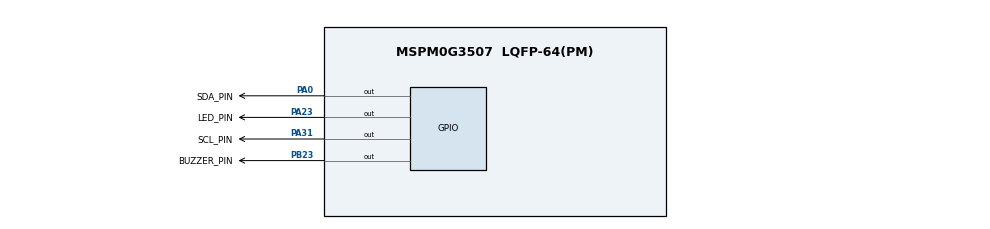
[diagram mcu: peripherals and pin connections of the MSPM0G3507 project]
/**
 * These arguments were used when this file was generated. They will be automatically applied on subsequent loads
 * via the GUI or CLI. Run CLI with '--help' for additional information on how to override these arguments.
 * @cliArgs --device "MSPM0G350X" --part "Default" --package "LQFP-64(PM)" --product "mspm0_sdk@2.11.00.07"
 * @v2CliArgs --device "MSPM0G3507" --package "LQFP-64(PM)" --product "mspm0_sdk@2.11.00.07"
 * @versions {"tool":"1.26.2+4477"}
 */

/**
 * Import the modules used in this configuration.
 */
const GPIO   = scripting.addModule("/ti/driverlib/GPIO", {}, false);
const GPIO1  = GPIO.addInstance();
const GPIO2  = GPIO.addInstance();
const GPIO3  = GPIO.addInstance();
const GPIO4  = GPIO.addInstance();
const SYSCTL = scripting.addModule("/ti/driverlib/SYSCTL");

/**
 * Write custom configuration values to the imported modules.
 */
GPIO1.$name                          = "LED";
GPIO1.associatedPins[0].$name        = "LED_PIN";
GPIO1.associatedPins[0].initialValue = "SET";
GPIO1.associatedPins[0].pin.$assign  = "PA23";

GPIO2.$name                         = "BUZZER";
GPIO2.associatedPins[0].$name       = "BUZZER_PIN";
GPIO2.associatedPins[0].pin.$assign = "PB23";

/* PA31 has no hardware I2C SCL multiplexing on MSPM0G3507. */
GPIO3.$name                         = "OLED_SCL";
GPIO3.associatedPins[0].$name       = "SCL_PIN";
GPIO3.associatedPins[0].pin.$assign = "PA31";

GPIO4.$name                         = "OLED_SDA";
GPIO4.associatedPins[0].$name       = "SDA_PIN";
GPIO4.associatedPins[0].pin.$assign = "PA0";

const Board = scripting.addModule("/ti/driverlib/Board", {}, false);

SYSCTL.forceDefaultClkConfig = true;

/**
 * Pinmux solution for unlocked pins/peripherals. This ensures that minor changes to the automatic solver in a future
 * version of the tool will not impact the pinmux you originally saw.  These lines can be completely deleted in order to
 * re-solve from scratch.
 */
Board.peripheral.$suggestSolution          = "DEBUGSS";
Board.peripheral.swclkPin.$suggestSolution = "PA20";
Board.peripheral.swdioPin.$suggestSolution = "PA19";
SYSCTL.peripheral.$suggestSolution         = "SYSCTL";
